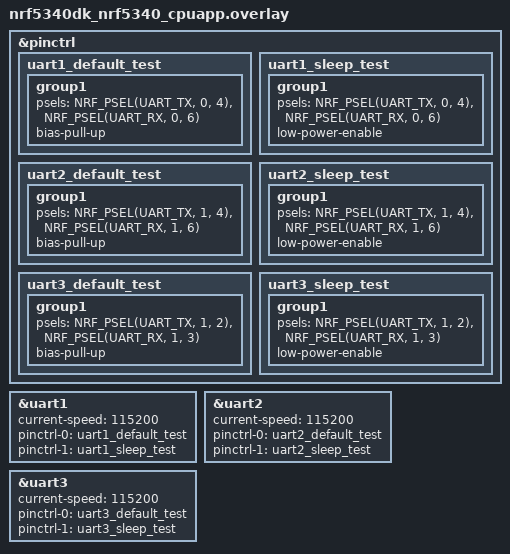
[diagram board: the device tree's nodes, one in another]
/*
 * Copyright (c) 2026 Nordic Semiconductor ASA
 *
 * SPDX-License-Identifier: LicenseRef-Nordic-5-Clause
 */

&pinctrl {
	uart1_default_test: uart1_default_test {
		group1 {
			psels = <NRF_PSEL(UART_TX, 0, 4)>,
				<NRF_PSEL(UART_RX, 0, 6)>;
			bias-pull-up;
		};
	};

	uart1_sleep_test: uart1_sleep_test {
		group1 {
			psels = <NRF_PSEL(UART_TX, 0, 4)>,
				<NRF_PSEL(UART_RX, 0, 6)>;
			low-power-enable;
		};
	};

	uart2_default_test: uart2_default_test {
		group1 {
			psels = <NRF_PSEL(UART_TX, 1, 4)>,
				<NRF_PSEL(UART_RX, 1, 6)>;
			bias-pull-up;
		};
	};

	uart2_sleep_test: uart2_sleep_test {
		group1 {
			psels = <NRF_PSEL(UART_TX, 1, 4)>,
				<NRF_PSEL(UART_RX, 1, 6)>;
			low-power-enable;
		};
	};

	uart3_default_test: uart3_default_test {
		group1 {
			psels = <NRF_PSEL(UART_TX, 1, 2)>,
				<NRF_PSEL(UART_RX, 1, 3)>;
			bias-pull-up;
		};
	};

	uart3_sleep_test: uart3_sleep_test {
		group1 {
			psels = <NRF_PSEL(UART_TX, 1, 2)>,
				<NRF_PSEL(UART_RX, 1, 3)>;
			low-power-enable;
		};
	};
};

&uart1 {
	status = "okay";
	current-speed = <115200>;
	pinctrl-0 = <&uart1_default_test>;
	pinctrl-1 = <&uart1_sleep_test>;
	pinctrl-names = "default", "sleep";
};

&uart2 {
	status = "okay";
	current-speed = <115200>;
	pinctrl-0 = <&uart2_default_test>;
	pinctrl-1 = <&uart2_sleep_test>;
	pinctrl-names = "default", "sleep";
};

&uart3 {
	status = "okay";
	current-speed = <115200>;
	pinctrl-0 = <&uart3_default_test>;
	pinctrl-1 = <&uart3_sleep_test>;
	pinctrl-names = "default", "sleep";
};
